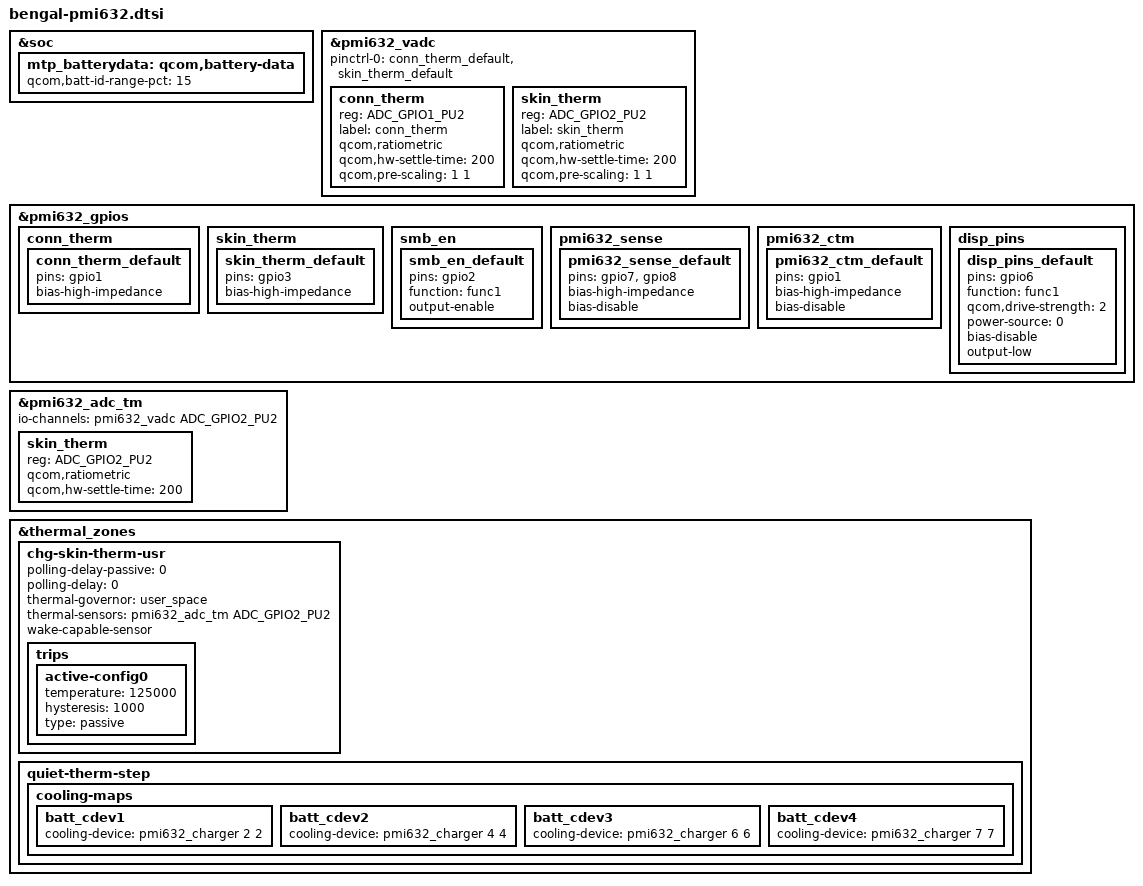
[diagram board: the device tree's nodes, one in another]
#include "pmi632.dtsi"

&soc {
	mtp_batterydata: qcom,battery-data {
		qcom,batt-id-range-pct = <15>;
		#include "qg-batterydata-alium-3600mah.dtsi"
	};
};

&pmi632_vadc {
	#address-cells = <1>;
	#size-cells = <0>;
	pinctrl-names = "default";
	pinctrl-0 = <&conn_therm_default &skin_therm_default>;

	conn_therm {
		reg = <ADC_GPIO1_PU2>;
		label = "conn_therm";
		qcom,ratiometric;
		qcom,hw-settle-time = <200>;
		qcom,pre-scaling = <1 1>;
	};

	skin_therm {
		reg = <ADC_GPIO2_PU2>;
		label = "skin_therm";
		qcom,ratiometric;
		qcom,hw-settle-time = <200>;
		qcom,pre-scaling = <1 1>;
	};
};

&pmi632_gpios {
	conn_therm {
		conn_therm_default: conn_therm_default {
			pins = "gpio1";
			bias-high-impedance;
		};
	};

	skin_therm {
		skin_therm_default: skin_therm_default {
			pins = "gpio3";
			bias-high-impedance;
		};
	};
};

&pmi632_adc_tm {
	#address-cells = <1>;
	#size-cells = <0>;
	io-channels = <&pmi632_vadc ADC_GPIO2_PU2>;

	/* Channel nodes */
	skin_therm {
		reg = <ADC_GPIO2_PU2>;
		qcom,ratiometric;
		qcom,hw-settle-time = <200>;
	};
};

&pmi632_gpios {
	smb_en {
		smb_en_default: smb_en_default {
			pins = "gpio2";
			function = "func1";
			output-enable;
		 };
	};

	pmi632_sense {
		/* GPIO 7 and 8 are external-sense pins for PMI632 */
		pmi632_sense_default: pmi632_sense_default {
			pins = "gpio7", "gpio8";
			bias-high-impedance;    /* disable the GPIO */
			bias-disable;           /* no-pull */
		};
	};

	pmi632_ctm {
		/* Disable GPIO1 for h/w base mitigation */
		pmi632_ctm_default: pmi632_ctm_default {
			pins = "gpio1";
			bias-high-impedance;    /* disable the GPIO */
			bias-disable;           /* no-pull */
		};
	};
};

&pmi632_gpios {
	disp_pins {
		disp_pins_default: disp_pins_default {
			pins = "gpio6";
			function = "func1";
			qcom,drive-strength = <2>;
			power-source = <0>;
			bias-disable;
			output-low;
		};
	};
};

&thermal_zones {
	chg-skin-therm-usr {
		polling-delay-passive = <0>;
		polling-delay = <0>;
		thermal-governor = "user_space";
		thermal-sensors = <&pmi632_adc_tm ADC_GPIO2_PU2>;
		wake-capable-sensor;
		trips {
			active-config0 {
				temperature = <125000>;
				hysteresis = <1000>;
				type = "passive";
			};
		};
	};

	quiet-therm-step {
		cooling-maps {
			batt_cdev1 {
				cooling-device = <&pmi632_charger 2 2>;
			};

			batt_cdev2 {
				cooling-device = <&pmi632_charger 4 4>;
			};

			batt_cdev3 {
				cooling-device = <&pmi632_charger 6 6>;
			};

			batt_cdev4 {
				cooling-device = <&pmi632_charger 7 7>;
			};
		};
	};
};
